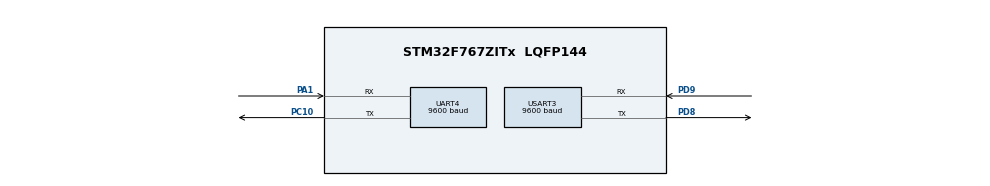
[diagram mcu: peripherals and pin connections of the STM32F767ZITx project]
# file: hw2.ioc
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Mcu.Family=STM32F7
Mcu.Name=STM32F767ZITx
Mcu.Package=LQFP144
NVIC.PriorityGroup=NVIC_PRIORITYGROUP_4
PA1.Mode=Asynchronous
PA1.Signal=UART4_RX
PC10.Mode=Asynchronous
PC10.Signal=UART4_TX
PD8.Mode=Asynchronous
PD8.Signal=USART3_TX
PD9.Mode=Asynchronous
PD9.Signal=USART3_RX
ProjectManager.HeapSize=0x200
ProjectManager.StackSize=0x400
ProjectManager.TargetToolchain=STM32CubeIDE
RCC.HSE_VALUE=25000000
RCC.HSI_VALUE=16000000
RCC.LSE_VALUE=32768
RCC.USBFreq_Value=96000000
RCC.VCOOutputFreq_Value=192000000
UART4.BaudRate=9600
UART4.Parity=PARITY_EVEN
UART4.WordLength=WORDLENGTH_9B
USART3.BaudRate=9600
USART3.Parity=PARITY_EVEN
USART3.VirtualMode-Asynchronous=VM_ASYNC
USART3.WordLength=WORDLENGTH_9B
board=custom

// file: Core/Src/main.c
/* USER CODE BEGIN Header */
/**
  ******************************************************************************
  * @file           : main.c
  * @brief          : Main program body
  ******************************************************************************
  * @attention
  *
  * <h2><center>&copy; Copyright (c) 2020 STMicroelectronics.
  * All rights reserved.</center></h2>
  *
  * This software component is licensed by ST under BSD 3-Clause license,
  * the "License"; You may not use this file except in compliance with the
  * License. You may obtain a copy of the License at:
  *                        opensource.org/licenses/BSD-3-Clause
  *
  ******************************************************************************
  */
/* USER CODE END Header */

#include "main.h"

UART_HandleTypeDef huart4;
UART_HandleTypeDef huart3;

void SystemClock_Config(void);
static void MX_GPIO_Init(void);
static void MX_UART4_Init(void);
static void MX_USART3_UART_Init(void);

int main(void)
{

  /* MCU Configuration--------------------------------------------------------*/

  /* Reset of all peripherals, Initializes the Flash interface and the Systick. */
  HAL_Init();

  /* Configure the system clock */
  SystemClock_Config();

  /* Initialize all configured peripherals */
  MX_GPIO_Init();
  MX_UART4_Init();
  MX_USART3_UART_Init();

  /* Infinite loop */
  /* USER CODE BEGIN WHILE */
  while (1)
  {
		char str[] = "02T";

		while (__HAL_UART_GET_FLAG(&huart3,UART_FLAG_TC)==RESET);
		while (__HAL_UART_GET_FLAG(&huart4,UART_FLAG_TC)==RESET);

		HAL_UART_Transmit(&huart3,(uint8_t*) str, strlen(str), 1000);
		HAL_UART_Transmit(&huart4,(uint8_t*) str, strlen(str), 1000);
		HAL_Delay(100);

    /* USER CODE END WHILE */

  }
}

void SystemClock_Config(void)
{
  RCC_OscInitTypeDef RCC_OscInitStruct = {0};
  RCC_ClkInitTypeDef RCC_ClkInitStruct = {0};
  RCC_PeriphCLKInitTypeDef PeriphClkInitStruct = {0};

  /** Configure the main internal regulator output voltage
  */
  __HAL_RCC_PWR_CLK_ENABLE();
  __HAL_PWR_VOLTAGESCALING_CONFIG(PWR_REGULATOR_VOLTAGE_SCALE3);
  /** Initializes the CPU, AHB and APB busses clocks
  */
  RCC_OscInitStruct.OscillatorType = RCC_OSCILLATORTYPE_HSI;
  RCC_OscInitStruct.HSIState = RCC_HSI_ON;
  RCC_OscInitStruct.HSICalibrationValue = RCC_HSICALIBRATION_DEFAULT;
  RCC_OscInitStruct.PLL.PLLState = RCC_PLL_NONE;
  if (HAL_RCC_OscConfig(&RCC_OscInitStruct) != HAL_OK)
  {
    Error_Handler();
  }
  /** Initializes the CPU, AHB and APB busses clocks
  */
  RCC_ClkInitStruct.ClockType = RCC_CLOCKTYPE_HCLK|RCC_CLOCKTYPE_SYSCLK
                              |RCC_CLOCKTYPE_PCLK1|RCC_CLOCKTYPE_PCLK2;
  RCC_ClkInitStruct.SYSCLKSource = RCC_SYSCLKSOURCE_HSI;
  RCC_ClkInitStruct.AHBCLKDivider = RCC_SYSCLK_DIV1;
  RCC_ClkInitStruct.APB1CLKDivider = RCC_HCLK_DIV1;
  RCC_ClkInitStruct.APB2CLKDivider = RCC_HCLK_DIV1;

  if (HAL_RCC_ClockConfig(&RCC_ClkInitStruct, FLASH_LATENCY_0) != HAL_OK)
  {
    Error_Handler();
  }
  PeriphClkInitStruct.PeriphClockSelection = RCC_PERIPHCLK_USART3|RCC_PERIPHCLK_UART4;
  PeriphClkInitStruct.Usart3ClockSelection = RCC_USART3CLKSOURCE_PCLK1;
  PeriphClkInitStruct.Uart4ClockSelection = RCC_UART4CLKSOURCE_PCLK1;
  if (HAL_RCCEx_PeriphCLKConfig(&PeriphClkInitStruct) != HAL_OK)
  {
    Error_Handler();
  }
}

static void MX_UART4_Init(void)
{

  huart4.Instance = UART4;
  huart4.Init.BaudRate = 9600;
  huart4.Init.WordLength = UART_WORDLENGTH_9B;
  huart4.Init.StopBits = UART_STOPBITS_1;
  huart4.Init.Parity = UART_PARITY_EVEN;
  huart4.Init.Mode = UART_MODE_TX_RX;
  huart4.Init.HwFlowCtl = UART_HWCONTROL_NONE;
  huart4.Init.OverSampling = UART_OVERSAMPLING_16;
  huart4.Init.OneBitSampling = UART_ONE_BIT_SAMPLE_DISABLE;
  huart4.AdvancedInit.AdvFeatureInit = UART_ADVFEATURE_NO_INIT;
  if (HAL_UART_Init(&huart4) != HAL_OK)
  {
    Error_Handler();
  }

}

static void MX_USART3_UART_Init(void)
{

  huart3.Instance = USART3;
  huart3.Init.BaudRate = 9600;
  huart3.Init.WordLength = UART_WORDLENGTH_9B;
  huart3.Init.StopBits = UART_STOPBITS_1;
  huart3.Init.Parity = UART_PARITY_EVEN;
  huart3.Init.Mode = UART_MODE_TX_RX;
  huart3.Init.HwFlowCtl = UART_HWCONTROL_NONE;
  huart3.Init.OverSampling = UART_OVERSAMPLING_16;
  huart3.Init.OneBitSampling = UART_ONE_BIT_SAMPLE_DISABLE;
  huart3.AdvancedInit.AdvFeatureInit = UART_ADVFEATURE_NO_INIT;
  if (HAL_UART_Init(&huart3) != HAL_OK)
  {
    Error_Handler();
  }

}

static void MX_GPIO_Init(void)
{

  /* GPIO Ports Clock Enable */
  __HAL_RCC_GPIOA_CLK_ENABLE();
  __HAL_RCC_GPIOD_CLK_ENABLE();
  __HAL_RCC_GPIOC_CLK_ENABLE();

}

void Error_Handler(void)
{
}

/************************ (C) COPYRIGHT STMicroelectronics *****END OF FILE****/
